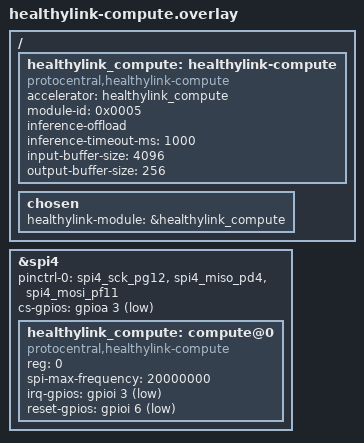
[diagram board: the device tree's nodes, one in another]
/*
 * HealthyLink Compute Module Overlay
 * Copyright (c) 2025 ProtoCentral
 * SPDX-License-Identifier: MIT
 *
 * External AI/ML compute module for inference offload
 * Module ID: 0x0005
 *
 * Supported Accelerators:
 *   - Google Coral Edge TPU (USB or SPI variants)
 *   - Custom FPGA/ASIC accelerators
 *   - Secondary MCU with dedicated ML capabilities
 *
 * Hardware Connections (STM32H757 Master):
 *   SPI4: PG12 (SCK), PD4 (MISO), PF11 (MOSI), PA3 (CS)
 *   GPIO: PI3 (IRQ/BUSY), PI6 (RESET)
 *
 * NPU Module (STM32N657 Slave):
 *   SPI5: PG12 (SCK), PD4 (MISO), PF11 (MOSI), PA3 (CS)
 *
 * Communication Protocol:
 *   SPI at up to 20 MHz for model input/output transfer
 *   IRQ signal indicates inference completion
 *
 * Usage:
 *   west build -b healthypi6_v2/stm32h757xx/m7 app_m7 \
 *       -DEXTRA_DTC_OVERLAY_FILE="boards/protocentral/healthypi6_v2/healthylink-compute.overlay"
 */

/* Include base HealthyLink definitions */
#include "healthylink.dtsi"

/* Enable SPI4 for HealthyLink Compute communication */
&spi4 {
	status = "okay";
	pinctrl-0 = <&spi4_sck_pg12 &spi4_miso_pd4 &spi4_mosi_pf11>;
	pinctrl-names = "default";

	/* Software chip select on PA3 */
	cs-gpios = <&gpioa 3 GPIO_ACTIVE_LOW>;

	/* HealthyLink Compute SPI Device
	 *
	 * This is a generic binding - actual implementation depends on
	 * the specific accelerator module installed. Common patterns:
	 *
	 * 1. Command-response protocol (like SPI flash)
	 * 2. Streaming protocol for real-time inference
	 * 3. Register-based configuration interface
	 *
	 * The driver should auto-detect accelerator type via EEPROM
	 * module-specific configuration at address 0x60-0x7F.
	 */
	healthylink_compute: compute@0 {
		compatible = "protocentral,healthylink-compute";
		reg = <0>;
		spi-max-frequency = <20000000>;  /* 20 MHz - adjust based on accelerator specs */

		/* Interrupt/busy signal from accelerator
		 * Active low: asserted when inference is complete or data is ready
		 */
		irq-gpios = <&gpioi 3 GPIO_ACTIVE_LOW>;

		/* Reset signal to accelerator
		 * Active low: pulse low to reset accelerator
		 */
		reset-gpios = <&gpioi 6 GPIO_ACTIVE_LOW>;

		status = "okay";
	};
};

/ {
	/* HealthyLink Compute module binding */
	healthylink_compute: healthylink-compute {
		compatible = "protocentral,healthylink-compute";
		status = "okay";

		/* Reference to the SPI accelerator device */
		accelerator = <&healthylink_compute>;

		/* Module identification */
		module-id = <0x0005>;

		/* Inference offload configuration
		 *
		 * When enabled, the M7/M4 can offload ML inference to this
		 * external accelerator. The workflow:
		 * 1. M7 prepares input tensor (e.g., preprocessed ECG beat)
		 * 2. M7 sends input to accelerator via SPI
		 * 3. Accelerator performs inference
		 * 4. Accelerator asserts IRQ when complete
		 * 5. M7 reads result via SPI
		 *
		 * This is useful for:
		 * - Models too large for on-chip memory
		 * - Models requiring >4 TOPS performance
		 * - Freeing M4 for real-time signal processing
		 */
		inference-offload;

		/* DMA channel for high-speed SPI transfers (optional)
		 * Enable DMA for transfers larger than threshold
		 */
		/* dma-threshold = <256>; */

		/* Maximum inference time in milliseconds
		 * Used for timeout detection
		 */
		inference-timeout-ms = <1000>;

		/* Input/output buffer sizes
		 * Must match accelerator's expected tensor dimensions
		 */
		input-buffer-size = <4096>;   /* Max input tensor size in bytes */
		output-buffer-size = <256>;   /* Max output tensor size in bytes */
	};

	/* Update chosen node for AI module */
	chosen {
		healthylink-module = &healthylink_compute;
	};
};
